# aes register map
Vendor: Texas Instruments
Peripheral module from a debugger description file (folder sc4e129bnczad).
Registers are 32-bit, read-write, no defined reset value unless marked. A register's access mark holds for its fields unless they carry their own. Offsets are as the file gives them; lines under a group give offsets from that group; [hi:lo] are bit positions; {n}, {i} and the like mark numbered series; 'fields as' and 'values as' point back to an identical list; <NAME> marks a mode.

## AES — AES register offsets
0x00 AES_KEY2_6
  [31:0] AES_KEY2_6_KEY — Key Data
0x04 AES_KEY2_7
  [31:0] AES_KEY2_7_KEY — Key Data
0x08 AES_KEY2_4
  [31:0] AES_KEY2_4_KEY — Key Data
0x0C AES_KEY2_5
  [31:0] AES_KEY2_5_KEY — Key Data
0x10 AES_KEY2_2
  [31:0] AES_KEY2_2_KEY — Key Data
0x14 AES_KEY2_3
  [31:0] AES_KEY2_3_KEY — Key Data
0x18 AES_KEY2_0
  [31:0] AES_KEY2_0_KEY — Key Data
0x1C AES_KEY2_1
  [31:0] AES_KEY2_1_KEY — Key Data
0x20 AES_KEY1_6
  [31:0] AES_KEY1_6_KEY — Key Data
0x24 AES_KEY1_7
  [31:0] AES_KEY1_7_KEY — Key Data
0x28 AES_KEY1_4
  [31:0] AES_KEY1_4_KEY — Key Data
0x2C AES_KEY1_5
  [31:0] AES_KEY1_5_KEY — Key Data
0x30 AES_KEY1_2
  [31:0] AES_KEY1_2_KEY — Key Data
0x34 AES_KEY1_3
  [31:0] AES_KEY1_3_KEY — Key Data
0x38 AES_KEY1_0
  [31:0] AES_KEY1_0_KEY — Key Data
0x3C AES_KEY1_1
  [31:0] AES_KEY1_1_KEY — Key Data
{0x40+4i} AES_IV_IN_{i} (i=0..3) — AES Initialization Vector Input {i}
  [31:0] AES_IV_IN_{i}_DATA — Initialization Vector Input
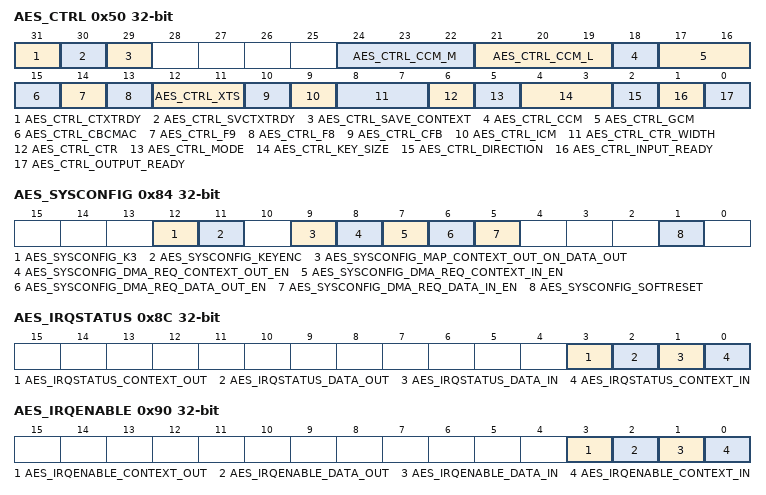
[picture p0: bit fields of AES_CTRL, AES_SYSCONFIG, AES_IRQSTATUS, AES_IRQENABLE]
0x50 AES_CTRL — AES Control
  [31] AES_CTRL_CTXTRDY — Context Data Registers Ready
  [30] AES_CTRL_SVCTXTRDY — AES TAG/IV Block(s) Ready
  [29] AES_CTRL_SAVE_CONTEXT — TAG or Result IV Save
  [24:22] AES_CTRL_CCM_M — Counter with CBC-MAC (CCM)
  [21:19] AES_CTRL_CCM_L — L Value
    1=width = 2; 3=width = 4; 7=width = 8
  [18] AES_CTRL_CCM — AES-CCM Mode Enable
  [17:16] AES_CTRL_GCM — AES-GCM Mode Enable
    0=AES_CTRL_GCM_NOP (No operation); 1=AES_CTRL_GCM_HLY0ZERO (GHASH with H loaded and Y0-encrypted forced to zero); 2=AES_CTRL_GCM_HLY0CALC (GHASH with H loaded and Y0-encrypted calculated internally); 3=AES_CTRL_GCM_HY0CALC (Autonomous GHASH (both H and Y0-encrypted calculated internally))
  [15] AES_CTRL_CBCMAC — AES-CBC MAC Enable
  [14] AES_CTRL_F9 — AES f9 Mode Enable
  [13] AES_CTRL_F8 — AES f8 Mode Enable
  [12:11] AES_CTRL_XTS — AES-XTS Operation Enabled
    0=AES_CTRL_XTS_NOP (No operation); 1=AES_CTRL_XTS_TWEAKJL (Previous/intermediate tweak value and j loaded (value is loaded via IV, j is loaded via the AAD length register)); 2=AES_CTRL_XTS_K2IJL (Key2, n and j are loaded (n is loaded via IV, j is loaded via the AAD length register)); 3=AES_CTRL_XTS_K2ILJ0 (Key2 and n are loaded; j=0 (n is loaded via IV))
  [10] AES_CTRL_CFB — Full block AES cipher feedback mode (CFB128) Enable
  [9] AES_CTRL_ICM — AES Integer Counter Mode (ICM) Enable
  [8:7] AES_CTRL_CTR_WIDTH — AES-CTR Mode Counter Width
    0=Counter is 32 bits; 1=Counter is 64 bits; 2=Counter is 96 bits; 3=Counter is 128 bits
  [6] AES_CTRL_CTR — Counter Mode
  [5] AES_CTRL_MODE — ECB/CBC Mode
  [4:3] AES_CTRL_KEY_SIZE — Key Size
    1=Key is 128 bits; 2=Key is 192 bits; 3=Key is 256 bits
  [2] AES_CTRL_DIRECTION — Encryption/Decryption Selection
  [1] AES_CTRL_INPUT_READY — Input Ready Status
  [0] AES_CTRL_OUTPUT_READY — Output Ready Status
0x54 AES_C_LENGTH_0 — AES Crypto Data Length 0
  [31:0] AES_C_LENGTH_0_LENGTH — Data Length
0x58 AES_C_LENGTH_1 — AES Crypto Data Length 1
  [31:0] AES_C_LENGTH_1_LENGTH — Data Length
0x5C AES_AUTH_LENGTH — AES Authentication Data Length
  [31:0] AES_AUTH_LENGTH_AUTH — Authentication Data Length
{0x60+4i} AES_DATA_IN_{i} (i=0..3) — AES Data RW Plaintext/Ciphertext {i}
  [31:0] AES_DATA_IN_{i}_DATA — Secure Data RW Plaintext/Ciphertext
{0x70+4i} AES_TAG_OUT_{i} (i=0..3) — AES Hash Tag Out {i}
  [31:0] AES_TAG_OUT_{i}_HASH — Hash Result
0x80 AES_REVISION ro — AES IP Revision Identifier
  [31:0] AES_REVISION — Revision number
0x84 AES_SYSCONFIG — AES System Configuration
  [12] AES_SYSCONFIG_K3 — K3 Select
  [11] AES_SYSCONFIG_KEYENC — Key Encoding
  [9] AES_SYSCONFIG_MAP_CONTEXT_OUT_ON_DATA_OUT — Map Context Out on Data Out Enable
  [8] AES_SYSCONFIG_DMA_REQ_CONTEXT_OUT_EN — DMA Request Context Out Enable
  [7] AES_SYSCONFIG_DMA_REQ_CONTEXT_IN_EN — DMA Request Context In Enable
  [6] AES_SYSCONFIG_DMA_REQ_DATA_OUT_EN — DMA Request Data Out Enable
  [5] AES_SYSCONFIG_DMA_REQ_DATA_IN_EN — DMA Request Data In Enable
  [1] AES_SYSCONFIG_SOFTRESET — Soft reset
0x88 AES_SYSSTATUS ro — AES System Status
  [0] AES_SYSSTATUS_RESETDONE — Reset Done
0x8C AES_IRQSTATUS ro — AES Interrupt Status
  [3] AES_IRQSTATUS_CONTEXT_OUT — Context Output Interrupt Status
  [2] AES_IRQSTATUS_DATA_OUT — Data Out Interrupt Status
  [1] AES_IRQSTATUS_DATA_IN — Data In Interrupt Status
  [0] AES_IRQSTATUS_CONTEXT_IN — Context In Interrupt Status
0x90 AES_IRQENABLE — AES Interrupt Enable
  [3] AES_IRQENABLE_CONTEXT_OUT — Context Out Interrupt Enable
  [2] AES_IRQENABLE_DATA_OUT — Data Out Interrupt Enable
  [1] AES_IRQENABLE_DATA_IN — Data In Interrupt Enable
  [0] AES_IRQENABLE_CONTEXT_IN — Context In Interrupt Enable
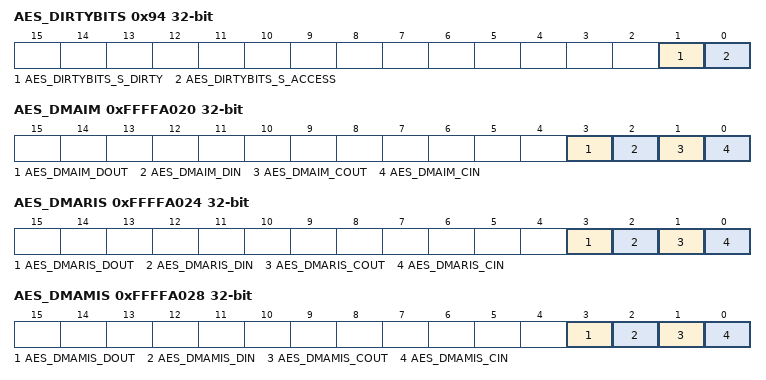
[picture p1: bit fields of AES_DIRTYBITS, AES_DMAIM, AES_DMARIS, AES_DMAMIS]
0x94 AES_DIRTYBITS
  [1] AES_DIRTYBITS_S_DIRTY — AES Dirty Bit
  [0] AES_DIRTYBITS_S_ACCESS — AES Access Bit
0xFFFFA020 AES_DMAIM — AES DMA Interrupt Mask
  [3] AES_DMAIM_DOUT — Data Out DMA Done Interrupt Mask
  [2] AES_DMAIM_DIN — Data In DMA Done Interrupt Mask
  [1] AES_DMAIM_COUT — Context Out DMA Done Interrupt Mask
  [0] AES_DMAIM_CIN — Context In DMA Done Interrupt Mask
0xFFFFA024 AES_DMARIS ro — AES DMA Raw Interrupt Status
  [3] AES_DMARIS_DOUT — Data Out DMA Done Raw Interrupt Status
  [2] AES_DMARIS_DIN — Data In DMA Done Raw Interrupt Status
  [1] AES_DMARIS_COUT — Context Out DMA Done Raw Interrupt Status
  [0] AES_DMARIS_CIN — Context In DMA Done Raw Interrupt Status
0xFFFFA028 AES_DMAMIS ro — AES DMA Masked Interrupt Status
  [3] AES_DMAMIS_DOUT — Data Out DMA Done Masked Interrupt Status
  [2] AES_DMAMIS_DIN — Data In DMA Done Masked Interrupt Status
  [1] AES_DMAMIS_COUT — Context Out DMA Done Masked Interrupt Status
  [0] AES_DMAMIS_CIN — Context In DMA Done Raw Interrupt Status
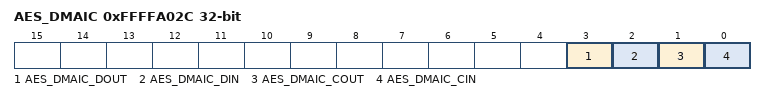
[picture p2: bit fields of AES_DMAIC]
0xFFFFA02C AES_DMAIC wo — AES DMA Interrupt Clear
  [3] AES_DMAIC_DOUT — Data Out DMA Done Interrupt Clear
  [2] AES_DMAIC_DIN — Data In DMA Done Interrupt Clear
  [1] AES_DMAIC_COUT — Context Out DMA Done Masked Interrupt Status
  [0] AES_DMAIC_CIN — Context In DMA Done Raw Interrupt Status
